# HSM_TC3xx register map
Vendor: Infineon; Series: AURIX TC3xx; File version: 2.0
CPU: CM3 r2p0, little endian, MPU, no FPU, 3 interrupt priority bits
Registers are 32-bit, read-write, no defined reset value unless marked. A register's access mark holds for its fields unless they carry their own. Offsets are from the block's base; [hi:lo] are bit positions.

## HSM_TIM — Timer module, timer 0 and timer 1 (HSM TS 7.4). 16-bit registers, addressed wordwise. Suspended in HALT mode.
Base 0xEC000000
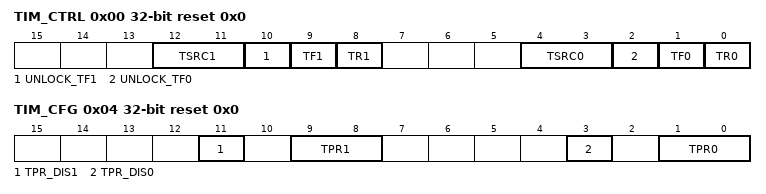
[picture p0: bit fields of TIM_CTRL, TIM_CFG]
0x00 TIM_CTRL reset 0x0 — Timer Control Register
  [12:11] TSRC1 — Timer 1 clock source (0-3)
  [10] UNLOCK_TF1 — Write enable for TF1 in the same access. Reads as 0.
  [9] TF1 — Timer 1 overflow flag
  [8] TR1 — Timer 1 run
  [4:3] TSRC0 — Timer 0 clock source (0-3)
  [2] UNLOCK_TF0 — Write enable for TF0 in the same access. Reads as 0.
  [1] TF0 — Timer 0 overflow flag
  [0] TR0 — Timer 0 run
0x04 TIM_CFG reset 0x0 — Timer Configuration Register (prescalers; change only while the timer is stopped)
  [11] TPR_DIS1 — Timer 1 prescaler disable
  [9:8] TPR1 — Timer 1 prescaler
    0=DIV4 (4); 1=DIV16 (16); 2=DIV64 (64); 3=DIV512 (512)
  [3] TPR_DIS0 — Timer 0 prescaler disable
  [1:0] TPR0 — Timer 0 prescaler
    0=DIV4 (4); 1=DIV16 (16); 2=DIV64 (64); 3=DIV512 (512)
0x10 TIM_CNT0 ro — Timer counter 0 register
  [15:0] COUNTER_VALUE — Current counter value
0x14 TIM_CNT1 ro — Timer counter 1 register
  [15:0] COUNTER_VALUE — Current counter value
0x20 TIM_RLD0 — Timer reload 0 register
  [15:0] RELOAD_VALUE
0x24 TIM_RLD1 — Timer reload 1 register
  [15:0] RELOAD_VALUE

## HSM_WDT — HSM watchdog timer (HSM TS 8.4). 16-bit registers, addressed wordwise. Suspended in HALT mode; its interrupt is the NMI.
Base 0xEC000100
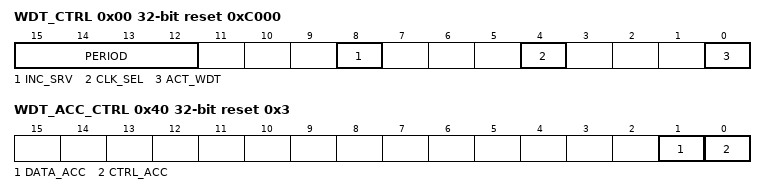
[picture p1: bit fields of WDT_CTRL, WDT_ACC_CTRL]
0x00 WDT_CTRL reset 0xC000 — Watchdog Timer Control Register
  [15:12] PERIOD — Watchdog period
  [8] INC_SRV — Increment service
    0=ISN (Service with 000AH); 1=IS1 (Service value incremented with each access)
  [4] CLK_SEL — Clock select (stop the watchdog before changing)
  [0] ACT_WDT — Watchdog running
0x10 WDT_VAL ro — Watchdog Timer Value Register
  [15:0] WDT_VAL — Current watchdog timer value
0x14 WDT_RELOAD — Watchdog Timer Reload Register
  [15:0] RELOAD_VAL — Reload value
0x18 WDT_SRV reset 0xA — Watchdog Service Register. A wrong value triggers a checkpoint mismatch; do not update by read-increment-write.
  [11:0] SRV_CNT — Service counter
0x1C WDT_SRV_INI wo — Watchdog Service Initialization Register
  [11:0] SRV_CNT_INI — Initial value of WDT_SRV
0x40 WDT_ACC_CTRL reset 0x3 — Watchdog Timer Access Control Register
  [1] DATA_ACC — Level for the data registers
    0=PRIV (Privileged); 1=USER
  [0] CTRL_ACC — Level for the control registers
    0=PRIV (Privileged); 1=USER

## HSM_TRNG — True random number generator (HSM TS 3.4). Suspended in HALT mode.
Base 0xEC000200
0x00 TRNG_DATA32 ro read-modifies — True RNG Data Register. A read consumes the random word (clears DTA_RDY), so it is not read automatically.
  [31:0] DATA — Random data
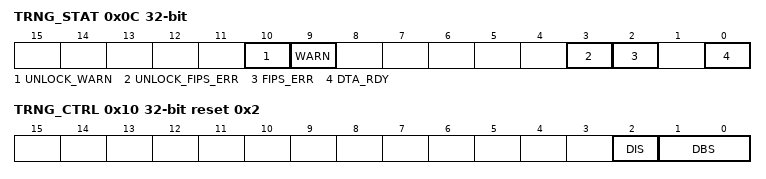
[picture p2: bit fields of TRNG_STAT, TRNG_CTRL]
0x0C TRNG_STAT — TRNG Status Register
  [10] UNLOCK_WARN — Write enable for WARN in the same access. Reads as 0.
  [9] WARN — Quality warning
    0=GOOD (No warning); 1=LOW (Random data quality inadequate)
  [3] UNLOCK_FIPS_ERR — Write enable for FIPS_ERR in the same access. Reads as 0.
  [2] FIPS_ERR — FIPS error
    0=OK (No error); 1=ERROR (Data identical to the previous word)
  [0] DTA_RDY — Random data ready
    0=BUSY (No data); 1=RDY (Data ready)
0x10 TRNG_CTRL reset 0x2 — TRNG Control Register
  [2] DIS — Disable (stops oscillators and logic)
  [1:0] DBS — Data block size
    0=BYTE (8 bits); 1=HW (16 bits); 2=WORD (32 bits)

## HSM_CACHE — HSM unified cache (HSM TS 2.5.3). Privileged access only. The command registers are write-only and trigger cache operations.
Base 0xE008A000
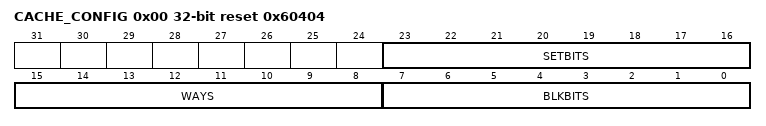
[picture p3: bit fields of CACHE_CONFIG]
0x00 CACHE_CONFIG ro reset 0x60404 — Cache Configuration Register
  [23:16] SETBITS — Number of set bits (2^SETBITS sets)
  [15:8] WAYS — Number of ways
  [7:0] BLKBITS — Number of block bits (04H: 16-byte lines)
0x04 CACHE_CTRL reset 0x0 — Cache Control Register
  [0] DAPCA — Disable parallel cache accesses
    0=EN (Parallel accesses possible); 1=DIS (Parallel accesses disabled)
0x100 CACHE_AC wo reset 0x0 — Cache All Clean Register (write: clean and invalidate all blocks)
  [31:0] MASK
0x104 CACHE_SC wo reset 0x0 — Cache Set Clean Register (write: clean the set of ADDR[9:4])
  [31:0] ADDR — Set address
0x110 CACHE_BC wo reset 0x0 — Cache Block Clean Register
  [31:0] ADDR — Block address (bits 3:0 ignored)
0x114 CACHE_BT wo reset 0x0 — Cache Block Touch Register
  [31:0] ADDR — Block address (bits 3:0 ignored)
0x118 CACHE_BL wo reset 0x0 — Cache Block Lock Register
  [31:0] ADDR — Block address (bits 3:0 ignored)
0x11C CACHE_BU wo reset 0x0 — Cache Block Unlock Register
  [31:0] ADDR — Block address (bits 3:0 ignored)
